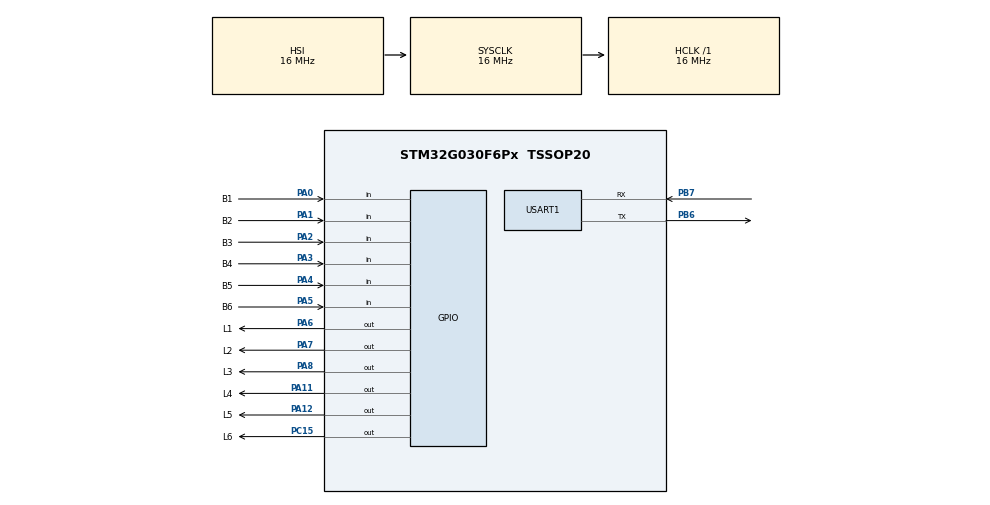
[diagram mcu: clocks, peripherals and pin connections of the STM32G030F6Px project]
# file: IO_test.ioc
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Mcu.Family=STM32G0
Mcu.Name=STM32G030F6Px
Mcu.Package=TSSOP20
PA0.GPIO_Label=B1
PA0.Signal=GPIO_Input
PA1.GPIO_Label=B2
PA1.Signal=GPIO_Input
PA11\ [PA9].GPIO_Label=L4
PA11\ [PA9].Signal=GPIO_Output
PA12\ [PA10].GPIO_Label=L5
PA12\ [PA10].Signal=GPIO_Output
PA13.Mode=Serial_Wire
PA13.Signal=SYS_SWDIO
PA14-BOOT0.Mode=Serial_Wire
PA14-BOOT0.Signal=SYS_SWCLK
PA14-BOOT0__PA15.StandardMode=true
PA2.GPIO_Label=B3
PA2.Signal=GPIO_Input
PA3.GPIO_Label=B4
PA3.Signal=GPIO_Input
PA4.GPIO_Label=B5
PA4.Signal=GPIO_Input
PA5.GPIO_Label=B6
PA5.Signal=GPIO_Input
PA6.GPIO_Label=L1
PA6.Signal=GPIO_Output
PA7.GPIO_Label=L2
PA7.Signal=GPIO_Output
PA8.GPIO_Label=L3
PA8.Signal=GPIO_Output
PB0__PB1__PB2__PA8.StandardMode=true
PB3__PB4__PB5__PB6.StandardMode=true
PB6.Mode=Asynchronous
PB6.Signal=USART1_TX
PB7.Mode=Asynchronous
PB7.Signal=USART1_RX
PB7__PB8.StandardMode=true
PC14-OSC32_IN\ (PC14)__PB9.StandardMode=true
PC15-OSC32_OUT\ (PC15).GPIO_Label=L6
PC15-OSC32_OUT\ (PC15).Signal=GPIO_Output
ProjectManager.HeapSize=0x200
ProjectManager.StackSize=0x400
ProjectManager.TargetToolchain=STM32CubeIDE
RCC.AHBFreq_Value=16000000
RCC.CortexFreq_Value=16000000
RCC.EXTERNAL_CLOCK_VALUE=12288000
RCC.HCLKFreq_Value=16000000
RCC.HSE_VALUE=8000000
RCC.HSI_VALUE=16000000
RCC.LSE_VALUE=32768
RCC.SYSCLKFreq_VALUE=16000000
RCC.VCOOutputFreq_Value=128000000
USART1.VirtualMode-Asynchronous=VM_ASYNC
board=custom

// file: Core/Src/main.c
/* USER CODE BEGIN Header */
/**
  ******************************************************************************
  * @file           : main.c
  * @brief          : Main program body
  ******************************************************************************
  * @attention
  *
  * Copyright (c) 2023 STMicroelectronics.
  * All rights reserved.
  *
  * This software is licensed under terms that can be found in the LICENSE file
  * in the root directory of this software component.
  * If no LICENSE file comes with this software, it is provided AS-IS.
  *
  ******************************************************************************
  */
/* USER CODE END Header */
#include "main.h"

UART_HandleTypeDef huart1;

void SystemClock_Config(void);
static void MX_GPIO_Init(void);
static void MX_USART1_UART_Init(void);

int main(void)
{

  /* MCU Configuration--------------------------------------------------------*/

  /* Reset of all peripherals, Initializes the Flash interface and the Systick. */
  HAL_Init();

  /* Configure the system clock */
  SystemClock_Config();

  /* Initialize all configured peripherals */
  MX_GPIO_Init();
  MX_USART1_UART_Init();

  /* Infinite loop */
  /* USER CODE BEGIN WHILE */
  while (1)
  {
	  for (int i = 0; i < 10; i++){
		  HAL_Delay(200);
		  if (HAL_GPIO_ReadPin(B1_GPIO_Port, B1_Pin))
			  HAL_GPIO_TogglePin(L1_GPIO_Port, L1_Pin);
		  if (HAL_GPIO_ReadPin(B2_GPIO_Port, B2_Pin))
			  HAL_GPIO_TogglePin(L2_GPIO_Port, L2_Pin);
		  if (HAL_GPIO_ReadPin(B3_GPIO_Port, B3_Pin))
			  HAL_GPIO_TogglePin(L3_GPIO_Port, L3_Pin);
		  if (HAL_GPIO_ReadPin(B4_GPIO_Port, B4_Pin))
			  HAL_GPIO_TogglePin(L4_GPIO_Port, L4_Pin);
		  if (HAL_GPIO_ReadPin(B5_GPIO_Port, B5_Pin))
			  HAL_GPIO_TogglePin(L5_GPIO_Port, L5_Pin);
		  if (HAL_GPIO_ReadPin(B6_GPIO_Port, B6_Pin))
			  HAL_GPIO_TogglePin(L6_GPIO_Port, L6_Pin);
	  }
    /* USER CODE END WHILE */

  }
}

void SystemClock_Config(void)
{
  RCC_OscInitTypeDef RCC_OscInitStruct = {0};
  RCC_ClkInitTypeDef RCC_ClkInitStruct = {0};

  /** Configure the main internal regulator output voltage
  */
  HAL_PWREx_ControlVoltageScaling(PWR_REGULATOR_VOLTAGE_SCALE1);

  /** Initializes the RCC Oscillators according to the specified parameters
  * in the RCC_OscInitTypeDef structure.
  */
  RCC_OscInitStruct.OscillatorType = RCC_OSCILLATORTYPE_HSI;
  RCC_OscInitStruct.HSIState = RCC_HSI_ON;
  RCC_OscInitStruct.HSIDiv = RCC_HSI_DIV1;
  RCC_OscInitStruct.HSICalibrationValue = RCC_HSICALIBRATION_DEFAULT;
  RCC_OscInitStruct.PLL.PLLState = RCC_PLL_NONE;
  if (HAL_RCC_OscConfig(&RCC_OscInitStruct) != HAL_OK)
  {
    Error_Handler();
  }

  /** Initializes the CPU, AHB and APB buses clocks
  */
  RCC_ClkInitStruct.ClockType = RCC_CLOCKTYPE_HCLK|RCC_CLOCKTYPE_SYSCLK
                              |RCC_CLOCKTYPE_PCLK1;
  RCC_ClkInitStruct.SYSCLKSource = RCC_SYSCLKSOURCE_HSI;
  RCC_ClkInitStruct.AHBCLKDivider = RCC_SYSCLK_DIV1;
  RCC_ClkInitStruct.APB1CLKDivider = RCC_HCLK_DIV1;

  if (HAL_RCC_ClockConfig(&RCC_ClkInitStruct, FLASH_LATENCY_0) != HAL_OK)
  {
    Error_Handler();
  }
}

static void MX_USART1_UART_Init(void)
{

  huart1.Instance = USART1;
  huart1.Init.BaudRate = 115200;
  huart1.Init.WordLength = UART_WORDLENGTH_8B;
  huart1.Init.StopBits = UART_STOPBITS_1;
  huart1.Init.Parity = UART_PARITY_NONE;
  huart1.Init.Mode = UART_MODE_TX_RX;
  huart1.Init.HwFlowCtl = UART_HWCONTROL_NONE;
  huart1.Init.OverSampling = UART_OVERSAMPLING_16;
  huart1.Init.OneBitSampling = UART_ONE_BIT_SAMPLE_DISABLE;
  huart1.Init.ClockPrescaler = UART_PRESCALER_DIV1;
  huart1.AdvancedInit.AdvFeatureInit = UART_ADVFEATURE_NO_INIT;
  if (HAL_UART_Init(&huart1) != HAL_OK)
  {
    Error_Handler();
  }
  if (HAL_UARTEx_SetTxFifoThreshold(&huart1, UART_TXFIFO_THRESHOLD_1_8) != HAL_OK)
  {
    Error_Handler();
  }
  if (HAL_UARTEx_SetRxFifoThreshold(&huart1, UART_RXFIFO_THRESHOLD_1_8) != HAL_OK)
  {
    Error_Handler();
  }
  if (HAL_UARTEx_DisableFifoMode(&huart1) != HAL_OK)
  {
    Error_Handler();
  }

}

static void MX_GPIO_Init(void)
{
  GPIO_InitTypeDef GPIO_InitStruct = {0};

  /* GPIO Ports Clock Enable */
  __HAL_RCC_GPIOB_CLK_ENABLE();
  __HAL_RCC_GPIOC_CLK_ENABLE();
  __HAL_RCC_GPIOA_CLK_ENABLE();

  /*Configure GPIO pin Output Level */
  HAL_GPIO_WritePin(L6_GPIO_Port, L6_Pin, GPIO_PIN_RESET);

  /*Configure GPIO pin Output Level */
  HAL_GPIO_WritePin(GPIOA, L1_Pin|L2_Pin|L3_Pin|L4_Pin
                          |L5_Pin, GPIO_PIN_RESET);

  /*Configure GPIO pins : B1_Pin B2_Pin B3_Pin B4_Pin
                           B5_Pin B6_Pin */
  GPIO_InitStruct.Pin = B1_Pin|B2_Pin|B3_Pin|B4_Pin
                          |B5_Pin|B6_Pin;
  GPIO_InitStruct.Mode = GPIO_MODE_INPUT;
  GPIO_InitStruct.Pull = GPIO_NOPULL;
  HAL_GPIO_Init(GPIOA, &GPIO_InitStruct);

  /*Configure GPIO pins : L1_Pin L2_Pin L3_Pin L4_Pin
                           L5_Pin */
  GPIO_InitStruct.Pin = L1_Pin|L2_Pin|L3_Pin|L4_Pin
                          |L5_Pin;
  GPIO_InitStruct.Mode = GPIO_MODE_OUTPUT_PP;
  GPIO_InitStruct.Pull = GPIO_NOPULL;
  GPIO_InitStruct.Speed = GPIO_SPEED_FREQ_LOW;
  HAL_GPIO_Init(GPIOA, &GPIO_InitStruct);

  /*Configure GPIO pin : L6_Pin */
  GPIO_InitStruct.Pin = L6_Pin;
  GPIO_InitStruct.Mode = GPIO_MODE_OUTPUT_PP;
  GPIO_InitStruct.Pull = GPIO_NOPULL;
  GPIO_InitStruct.Speed = GPIO_SPEED_FREQ_LOW;
  HAL_GPIO_Init(L6_GPIO_Port, &GPIO_InitStruct);

}

void Error_Handler(void)
{
  __disable_irq();
  while (1)
  {
  }
}
